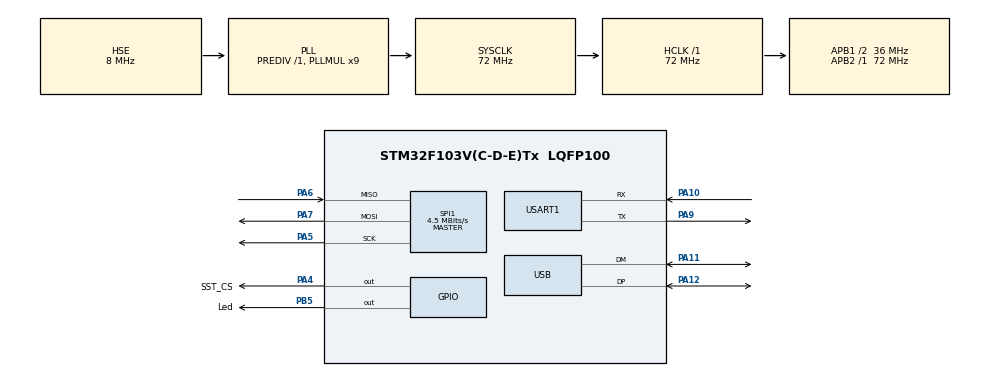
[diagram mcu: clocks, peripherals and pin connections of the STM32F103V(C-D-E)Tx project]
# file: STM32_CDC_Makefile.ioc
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Mcu.Family=STM32F1
Mcu.Name=STM32F103V(C-D-E)Tx
Mcu.Package=LQFP100
NVIC.PriorityGroup=NVIC_PRIORITYGROUP_4
NVIC.TIM1_UP_IRQn=true\:0\:0\:false\:false\:true\:false\:true
NVIC.TimeBase=TIM1_UP_IRQn
NVIC.TimeBaseIP=TIM1
NVIC.USB_LP_CAN1_RX0_IRQn=true\:0\:0\:false\:false\:true\:false\:true
OSC_IN.Mode=HSE-External-Oscillator
OSC_IN.Signal=RCC_OSC_IN
OSC_OUT.Mode=HSE-External-Oscillator
OSC_OUT.Signal=RCC_OSC_OUT
PA10.Mode=Asynchronous
PA10.Signal=USART1_RX
PA11.Mode=Device
PA11.Signal=USB_DM
PA12.Mode=Device
PA12.Signal=USB_DP
PA4.GPIO_Label=SST_CS
PA4.GPIO_Speed=GPIO_SPEED_FREQ_HIGH
PA4.Signal=GPIO_Output
PA5.Mode=Full_Duplex_Master
PA5.Signal=SPI1_SCK
PA6.Mode=Full_Duplex_Master
PA6.Signal=SPI1_MISO
PA7.Mode=Full_Duplex_Master
PA7.Signal=SPI1_MOSI
PA9.Mode=Asynchronous
PA9.Signal=USART1_TX
PB5.GPIO_Label=Led
PB5.Signal=GPIO_Output
PC14-OSC32_IN.Mode=LSE-External-Oscillator
PC14-OSC32_IN.Signal=RCC_OSC32_IN
PC15-OSC32_OUT.Mode=LSE-External-Oscillator
PC15-OSC32_OUT.Signal=RCC_OSC32_OUT
ProjectManager.HeapSize=0x2000
ProjectManager.StackSize=0x4000
ProjectManager.TargetToolchain=Makefile
RCC.AHBFreq_Value=72000000
RCC.APB1CLKDivider=RCC_HCLK_DIV2
RCC.APB1Freq_Value=36000000
RCC.APB1TimFreq_Value=72000000
RCC.APB2Freq_Value=72000000
RCC.APB2TimFreq_Value=72000000
RCC.HCLKFreq_Value=72000000
RCC.PLLMUL=RCC_PLL_MUL9
RCC.PLLSourceVirtual=RCC_PLLSOURCE_HSE
RCC.SYSCLKFreq_VALUE=72000000
RCC.SYSCLKSource=RCC_SYSCLKSOURCE_PLLCLK
RCC.USBFreq_Value=48000000
RCC.USBPrescaler=RCC_USBCLKSOURCE_PLL_DIV1_5
SPI1.BaudRatePrescaler=SPI_BAUDRATEPRESCALER_16
SPI1.CLKPolarity=SPI_POLARITY_HIGH
SPI1.CalculateBaudRate=4.5 MBits/s
SPI1.Direction=SPI_DIRECTION_2LINES
SPI1.Mode=SPI_MODE_MASTER
SPI1.VirtualType=VM_MASTER
USART1.VirtualMode=VM_ASYNC
USB_DEVICE.CLASS_NAME_FS=CDC
USB_DEVICE.VirtualMode=Cdc
USB_DEVICE.VirtualModeFS=Cdc_FS
VP_SYS_VS_ND.Mode=No_Debug
VP_SYS_VS_tim1.Mode=TIM1
VP_USB_DEVICE_VS_USB_DEVICE_CDC_FS.Mode=CDC_FS
board=custom

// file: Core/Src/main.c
/* USER CODE BEGIN Header */
/**
  ******************************************************************************
  * @file           : main.c
  * @brief          : Main program body
  ******************************************************************************
  * @attention
  *
  * <h2><center>&copy; Copyright (c) 2019 STMicroelectronics.
  * All rights reserved.</center></h2>
  *
  * This software component is licensed by ST under Ultimate Liberty license
  * SLA0044, the "License"; You may not use this file except in compliance with
  * the License. You may obtain a copy of the License at:
  *                             www.st.com/SLA0044
  *
  ******************************************************************************
  */
/* USER CODE END Header */

#include "main.h"
#include "spi.h"
#include "usart.h"
#include "usb_device.h"
#include "gpio.h"

/* USER CODE BEGIN Includes */
#include "eeprom.h"
/* USER CODE END Includes */

void SystemClock_Config(void);

int main(void)
{

  /* MCU Configuration--------------------------------------------------------*/

  /* Reset of all peripherals, Initializes the Flash interface and the Systick. */
  HAL_Init();

  /* Configure the system clock */
  SystemClock_Config();

  /* Initialize all configured peripherals */
  MX_GPIO_Init();
  MX_SPI1_Init();
  MX_USB_DEVICE_Init();
  MX_USART1_UART_Init();
  /* USER CODE BEGIN 2 */
  HAL_Delay(2000);
  if (EEPROMIsValid() == 0) {
    uartprintf("EEPROM Id check is failed\r\n");
    return -1;
  }

  uartprintf("Running backup task\r\n");
  /* USER CODE END 2 */

  /* Infinite loop */
  while (1)
  {

  }
}

void SystemClock_Config(void)
{
  RCC_OscInitTypeDef RCC_OscInitStruct = {0};
  RCC_ClkInitTypeDef RCC_ClkInitStruct = {0};
  RCC_PeriphCLKInitTypeDef PeriphClkInit = {0};

  /** Initializes the CPU, AHB and APB busses clocks
  */
  RCC_OscInitStruct.OscillatorType = RCC_OSCILLATORTYPE_HSE;
  RCC_OscInitStruct.HSEState = RCC_HSE_ON;
  RCC_OscInitStruct.HSEPredivValue = RCC_HSE_PREDIV_DIV1;
  RCC_OscInitStruct.HSIState = RCC_HSI_ON;
  RCC_OscInitStruct.PLL.PLLState = RCC_PLL_ON;
  RCC_OscInitStruct.PLL.PLLSource = RCC_PLLSOURCE_HSE;
  RCC_OscInitStruct.PLL.PLLMUL = RCC_PLL_MUL9;
  if (HAL_RCC_OscConfig(&RCC_OscInitStruct) != HAL_OK)
  {
    Error_Handler();
  }
  /** Initializes the CPU, AHB and APB busses clocks
  */
  RCC_ClkInitStruct.ClockType = RCC_CLOCKTYPE_HCLK|RCC_CLOCKTYPE_SYSCLK
                              |RCC_CLOCKTYPE_PCLK1|RCC_CLOCKTYPE_PCLK2;
  RCC_ClkInitStruct.SYSCLKSource = RCC_SYSCLKSOURCE_PLLCLK;
  RCC_ClkInitStruct.AHBCLKDivider = RCC_SYSCLK_DIV1;
  RCC_ClkInitStruct.APB1CLKDivider = RCC_HCLK_DIV2;
  RCC_ClkInitStruct.APB2CLKDivider = RCC_HCLK_DIV1;

  if (HAL_RCC_ClockConfig(&RCC_ClkInitStruct, FLASH_LATENCY_2) != HAL_OK)
  {
    Error_Handler();
  }
  PeriphClkInit.PeriphClockSelection = RCC_PERIPHCLK_USB;
  PeriphClkInit.UsbClockSelection = RCC_USBCLKSOURCE_PLL_DIV1_5;
  if (HAL_RCCEx_PeriphCLKConfig(&PeriphClkInit) != HAL_OK)
  {
    Error_Handler();
  }
}

void HAL_TIM_PeriodElapsedCallback(TIM_HandleTypeDef *htim)
{
  if (htim->Instance == TIM1) {
    HAL_IncTick();
  }
}

void Error_Handler(void)
{
}

/************************ (C) COPYRIGHT STMicroelectronics *****END OF FILE****/
